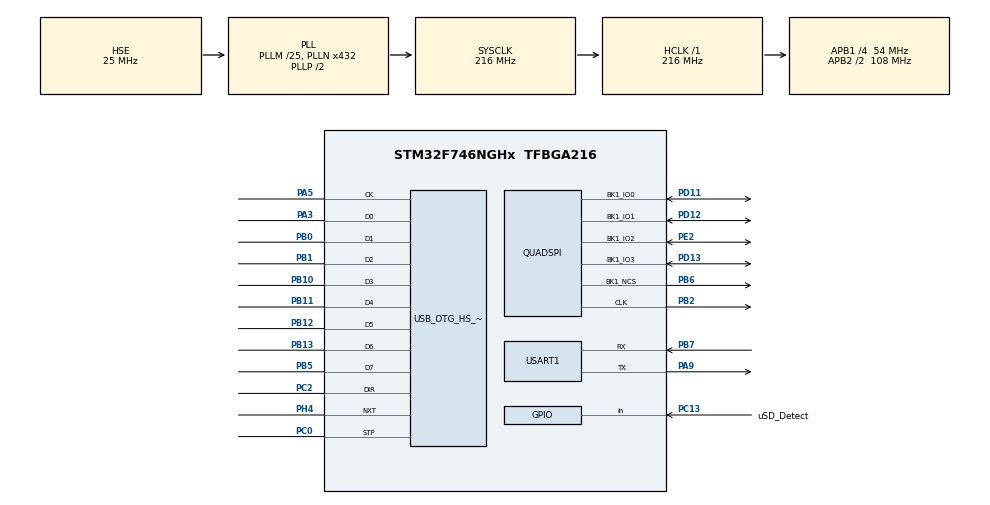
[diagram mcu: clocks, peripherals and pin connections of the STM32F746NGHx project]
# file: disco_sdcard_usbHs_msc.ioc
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CORTEX_M7.AccessPermission_Spec=MPU_REGION_FULL_ACCESS
CORTEX_M7.CPU_DCache=Enabled
CORTEX_M7.CPU_ICache=Enabled
CORTEX_M7.default_mode_Activation=1
Mcu.Family=STM32F7
Mcu.Name=STM32F746NGHx
Mcu.Package=TFBGA216
NVIC.OTG_HS_IRQn=true\:0\:0\:false\:false\:true\:false\:true\:true
NVIC.PriorityGroup=NVIC_PRIORITYGROUP_4
NVIC.QUADSPI_IRQn=true\:0\:0\:false\:false\:true\:true\:true\:true
NVIC.TIM7_IRQn=true\:15\:0\:false\:false\:true\:false\:true\:true
NVIC.TimeBase=TIM7_IRQn
NVIC.TimeBaseIP=TIM7
NVIC.USART1_IRQn=true\:0\:0\:false\:false\:true\:true\:true\:true
PA13.Mode=Serial_Wire
PA13.Signal=SYS_JTMS-SWDIO
PA14.Mode=Serial_Wire
PA14.Signal=SYS_JTCK-SWCLK
PA3.Mode=Device_HS
PA3.Signal=USB_OTG_HS_ULPI_D0
PA5.Mode=Device_HS
PA5.Signal=USB_OTG_HS_ULPI_CK
PA9.Mode=Asynchronous
PA9.Signal=USART1_TX
PB0.Mode=Device_HS
PB0.Signal=USB_OTG_HS_ULPI_D1
PB1.Mode=Device_HS
PB1.Signal=USB_OTG_HS_ULPI_D2
PB10.Mode=Device_HS
PB10.Signal=USB_OTG_HS_ULPI_D3
PB11.Mode=Device_HS
PB11.Signal=USB_OTG_HS_ULPI_D4
PB12.Mode=Device_HS
PB12.Signal=USB_OTG_HS_ULPI_D5
PB13.Mode=Device_HS
PB13.Signal=USB_OTG_HS_ULPI_D6
PB2.Mode=Single Bank 1
PB2.Signal=QUADSPI_CLK
PB5.Mode=Device_HS
PB5.Signal=USB_OTG_HS_ULPI_D7
PB6.Mode=Single Bank 1
PB6.Signal=QUADSPI_BK1_NCS
PB7.Mode=Asynchronous
PB7.Signal=USART1_RX
PC0.Mode=Device_HS
PC0.Signal=USB_OTG_HS_ULPI_STP
PC13.GPIO_Label=uSD_Detect
PC13.Signal=GPIO_Input
PC14/OSC32_IN.Mode=LSE-External-Oscillator
PC14/OSC32_IN.Signal=RCC_OSC32_IN
PC15/OSC32_OUT.Mode=LSE-External-Oscillator
PC15/OSC32_OUT.Signal=RCC_OSC32_OUT
PC2.Mode=Device_HS
PC2.Signal=USB_OTG_HS_ULPI_DIR
PC3.Signal=FMC_SDCKE0
PD11.Mode=Single Bank 1
PD11.Signal=QUADSPI_BK1_IO0
PD12.Mode=Single Bank 1
PD12.Signal=QUADSPI_BK1_IO1
PD13.Mode=Single Bank 1
PD13.Signal=QUADSPI_BK1_IO3
PE2.Mode=Single Bank 1
PE2.Signal=QUADSPI_BK1_IO2
PH0/OSC_IN.Mode=HSE-External-Oscillator
PH0/OSC_IN.Signal=RCC_OSC_IN
PH1/OSC_OUT.Mode=HSE-External-Oscillator
PH1/OSC_OUT.Signal=RCC_OSC_OUT
PH4.Mode=Device_HS
PH4.Signal=USB_OTG_HS_ULPI_NXT
ProjectManager.HeapSize=0x400
ProjectManager.StackSize=0x800
ProjectManager.TargetToolchain=STM32CubeIDE
RCC.AHBFreq_Value=216000000
RCC.APB1CLKDivider=RCC_HCLK_DIV4
RCC.APB1Freq_Value=54000000
RCC.APB1TimFreq_Value=108000000
RCC.APB2CLKDivider=RCC_HCLK_DIV2
RCC.APB2Freq_Value=108000000
RCC.APB2TimFreq_Value=216000000
RCC.CortexFreq_Value=216000000
RCC.HCLKFreq_Value=216000000
RCC.HSE_VALUE=25000000
RCC.HSI_VALUE=16000000
RCC.PLL48CLockSelection=RCC_CLK48SOURCE_PLLSAIP
RCC.PLLI2SN=100
RCC.PLLM=25
RCC.PLLN=432
RCC.PLLQ=8
RCC.PLLSAIP=RCC_PLLSAIP_DIV4
RCC.PLLSAIR=5
RCC.PLLSAIRDiv=RCC_PLLSAIDIVR_8
RCC.PLLSourceVirtual=RCC_PLLSOURCE_HSE
RCC.SDMMCClockSelection=RCC_SDMMC1CLKSOURCE_CLK48
RCC.SYSCLKFreq_VALUE=216000000
RCC.SYSCLKSource=RCC_SYSCLKSOURCE_PLLCLK
RCC.USBFreq_Value=48000000
RCC.VCOOutputFreq_Value=432000000
USART1.VirtualMode-Asynchronous=VM_ASYNC
USB_DEVICE.CLASS_NAME_HS=MSC
USB_DEVICE.MSC_MEDIA_PACKET-MSC_HS=4096
USB_DEVICE.VirtualMode-MSC_HS=Msc
USB_DEVICE.VirtualModeHS=Msc_HS
USB_OTG_HS.VirtualMode-Device_HS=Device_HS
VP_SYS_VS_tim7.Mode=TIM7
VP_USB_DEVICE_VS_USB_DEVICE_MSC_HS.Mode=MSC_HS
board=STM32F746G-DISCO

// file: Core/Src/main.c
/* USER CODE BEGIN Header */
/**
 ******************************************************************************
 * @file           : main.c
 * @brief          : Main program body
 ******************************************************************************
 * @attention
 *
 * Copyright (c) 2025 STMicroelectronics.
 * All rights reserved.
 *
 * This software is licensed under terms that can be found in the LICENSE file
 * in the root directory of this software component.
 * If no LICENSE file comes with this software, it is provided AS-IS.
 *
 ******************************************************************************
 */
/* USER CODE END Header */
#include "main.h"
#include "usb_device.h"

/* USER CODE BEGIN Includes */
#include <stdio.h>
#include "../../Drivers/BSP/stm32746g_discovery_qspi.h"

/* USER CODE END Includes */

QSPI_HandleTypeDef hqspi;

UART_HandleTypeDef huart1;

/* USER CODE BEGIN PV */
int _write(int file, char *ptr, int len) {
    for (int i = 0; i < len; i++) {
        HAL_UART_Transmit(&huart1, (uint8_t *)&ptr[i], 1, HAL_MAX_DELAY);
    }
    return len;
}

/* USER CODE END PV */

void SystemClock_Config(void);
static void MPU_Config(void);
static void MX_GPIO_Init(void);
static void MX_USART1_UART_Init(void);
static void MX_QUADSPI_Init(void);

int main(void)
{

  /* MPU Configuration--------------------------------------------------------*/
  MPU_Config();

  /* Enable the CPU Cache */

  /* Enable I-Cache---------------------------------------------------------*/
  SCB_EnableICache();

  /* Enable D-Cache---------------------------------------------------------*/
  SCB_EnableDCache();

  /* MCU Configuration--------------------------------------------------------*/

  /* Reset of all peripherals, Initializes the Flash interface and the Systick. */
  HAL_Init();

  /* Configure the system clock */
  SystemClock_Config();

  /* Initialize all configured peripherals */
  MX_GPIO_Init();
  MX_USART1_UART_Init();
  MX_QUADSPI_Init();
  MX_USB_DEVICE_Init();
  /* USER CODE BEGIN 2 */
  setvbuf(stdout, NULL, _IONBF, 0);
  BSP_QSPI_Init();
  MX_USB_DEVICE_Init();
  //erase_all_sector();
  /* USER CODE END 2 */

  /* Infinite loop */
  /* USER CODE BEGIN WHILE */

  /* Fill the write buffer with some data */
  //int  hi=0;
	while (1) {
	 // printf("hi %i\r\n",hi++);
	  HAL_Delay(5000);

    /* USER CODE END WHILE */

	}
}

void SystemClock_Config(void)
{
  RCC_OscInitTypeDef RCC_OscInitStruct = {0};
  RCC_ClkInitTypeDef RCC_ClkInitStruct = {0};

  /** Configure LSE Drive Capability
  */
  HAL_PWR_EnableBkUpAccess();

  /** Configure the main internal regulator output voltage
  */
  __HAL_RCC_PWR_CLK_ENABLE();
  __HAL_PWR_VOLTAGESCALING_CONFIG(PWR_REGULATOR_VOLTAGE_SCALE1);

  /** Initializes the RCC Oscillators according to the specified parameters
  * in the RCC_OscInitTypeDef structure.
  */
  RCC_OscInitStruct.OscillatorType = RCC_OSCILLATORTYPE_HSE;
  RCC_OscInitStruct.HSEState = RCC_HSE_ON;
  RCC_OscInitStruct.PLL.PLLState = RCC_PLL_ON;
  RCC_OscInitStruct.PLL.PLLSource = RCC_PLLSOURCE_HSE;
  RCC_OscInitStruct.PLL.PLLM = 25;
  RCC_OscInitStruct.PLL.PLLN = 432;
  RCC_OscInitStruct.PLL.PLLP = RCC_PLLP_DIV2;
  RCC_OscInitStruct.PLL.PLLQ = 8;
  if (HAL_RCC_OscConfig(&RCC_OscInitStruct) != HAL_OK)
  {
    Error_Handler();
  }

  /** Activate the Over-Drive mode
  */
  if (HAL_PWREx_EnableOverDrive() != HAL_OK)
  {
    Error_Handler();
  }

  /** Initializes the CPU, AHB and APB buses clocks
  */
  RCC_ClkInitStruct.ClockType = RCC_CLOCKTYPE_HCLK|RCC_CLOCKTYPE_SYSCLK
                              |RCC_CLOCKTYPE_PCLK1|RCC_CLOCKTYPE_PCLK2;
  RCC_ClkInitStruct.SYSCLKSource = RCC_SYSCLKSOURCE_PLLCLK;
  RCC_ClkInitStruct.AHBCLKDivider = RCC_SYSCLK_DIV1;
  RCC_ClkInitStruct.APB1CLKDivider = RCC_HCLK_DIV4;
  RCC_ClkInitStruct.APB2CLKDivider = RCC_HCLK_DIV2;

  if (HAL_RCC_ClockConfig(&RCC_ClkInitStruct, FLASH_LATENCY_7) != HAL_OK)
  {
    Error_Handler();
  }
}

static void MX_QUADSPI_Init(void)
{

  /* QUADSPI parameter configuration*/
  hqspi.Instance = QUADSPI;
  hqspi.Init.ClockPrescaler = 255;
  hqspi.Init.FifoThreshold = 1;
  hqspi.Init.SampleShifting = QSPI_SAMPLE_SHIFTING_NONE;
  hqspi.Init.FlashSize = 1;
  hqspi.Init.ChipSelectHighTime = QSPI_CS_HIGH_TIME_1_CYCLE;
  hqspi.Init.ClockMode = QSPI_CLOCK_MODE_0;
  hqspi.Init.FlashID = QSPI_FLASH_ID_1;
  hqspi.Init.DualFlash = QSPI_DUALFLASH_DISABLE;
  if (HAL_QSPI_Init(&hqspi) != HAL_OK)
  {
    Error_Handler();
  }

}

static void MX_USART1_UART_Init(void)
{

  huart1.Instance = USART1;
  huart1.Init.BaudRate = 115200;
  huart1.Init.WordLength = UART_WORDLENGTH_8B;
  huart1.Init.StopBits = UART_STOPBITS_1;
  huart1.Init.Parity = UART_PARITY_NONE;
  huart1.Init.Mode = UART_MODE_TX_RX;
  huart1.Init.HwFlowCtl = UART_HWCONTROL_NONE;
  huart1.Init.OverSampling = UART_OVERSAMPLING_16;
  huart1.Init.OneBitSampling = UART_ONE_BIT_SAMPLE_DISABLE;
  huart1.AdvancedInit.AdvFeatureInit = UART_ADVFEATURE_NO_INIT;
  if (HAL_UART_Init(&huart1) != HAL_OK)
  {
    Error_Handler();
  }

}

static void MX_GPIO_Init(void)
{
  GPIO_InitTypeDef GPIO_InitStruct = {0};

  /* GPIO Ports Clock Enable */
  __HAL_RCC_GPIOE_CLK_ENABLE();
  __HAL_RCC_GPIOB_CLK_ENABLE();
  __HAL_RCC_GPIOA_CLK_ENABLE();
  __HAL_RCC_GPIOC_CLK_ENABLE();
  __HAL_RCC_GPIOH_CLK_ENABLE();
  __HAL_RCC_GPIOD_CLK_ENABLE();

  /*Configure GPIO pin : uSD_Detect_Pin */
  GPIO_InitStruct.Pin = uSD_Detect_Pin;
  GPIO_InitStruct.Mode = GPIO_MODE_INPUT;
  GPIO_InitStruct.Pull = GPIO_NOPULL;
  HAL_GPIO_Init(uSD_Detect_GPIO_Port, &GPIO_InitStruct);

  /*Configure GPIO pin : PC3 */
  GPIO_InitStruct.Pin = GPIO_PIN_3;
  GPIO_InitStruct.Mode = GPIO_MODE_AF_PP;
  GPIO_InitStruct.Pull = GPIO_NOPULL;
  GPIO_InitStruct.Speed = GPIO_SPEED_FREQ_VERY_HIGH;
  GPIO_InitStruct.Alternate = GPIO_AF12_FMC;
  HAL_GPIO_Init(GPIOC, &GPIO_InitStruct);

}

 /* MPU Configuration */

void MPU_Config(void)
{
  MPU_Region_InitTypeDef MPU_InitStruct = {0};

  /* Disables the MPU */
  HAL_MPU_Disable();

  /** Initializes and configures the Region and the memory to be protected
  */
  MPU_InitStruct.Enable = MPU_REGION_ENABLE;
  MPU_InitStruct.Number = MPU_REGION_NUMBER0;
  MPU_InitStruct.BaseAddress = 0x0;
  MPU_InitStruct.Size = MPU_REGION_SIZE_4GB;
  MPU_InitStruct.SubRegionDisable = 0x87;
  MPU_InitStruct.TypeExtField = MPU_TEX_LEVEL0;
  MPU_InitStruct.AccessPermission = MPU_REGION_FULL_ACCESS;
  MPU_InitStruct.DisableExec = MPU_INSTRUCTION_ACCESS_DISABLE;
  MPU_InitStruct.IsShareable = MPU_ACCESS_SHAREABLE;
  MPU_InitStruct.IsCacheable = MPU_ACCESS_NOT_CACHEABLE;
  MPU_InitStruct.IsBufferable = MPU_ACCESS_NOT_BUFFERABLE;

  HAL_MPU_ConfigRegion(&MPU_InitStruct);
  /* Enables the MPU */
  HAL_MPU_Enable(MPU_PRIVILEGED_DEFAULT);

}

void HAL_TIM_PeriodElapsedCallback(TIM_HandleTypeDef *htim)
{
  if (htim->Instance == TIM7) {
    HAL_IncTick();
  }
}

void Error_Handler(void)
{
	__disable_irq();
	while (1) {
	}
}

#ifdef  USE_FULL_ASSERT
/**
  * @brief  Reports the name of the source file and the source line number
  *         where the assert_param error has occurred.
  * @param  file: pointer to the source file name
  * @param  line: assert_param error line source number
  * @retval None
  */
void assert_failed(uint8_t *file, uint32_t line)
{
  /* USER CODE BEGIN 6 */
  /* User can add his own implementation to report the file name and line number,
     ex: UART_Print("Wrong parameters value: file %s on line %d\r\n", file, line) */
  /* USER CODE END 6 */
}
#endif /* USE_FULL_ASSERT */
